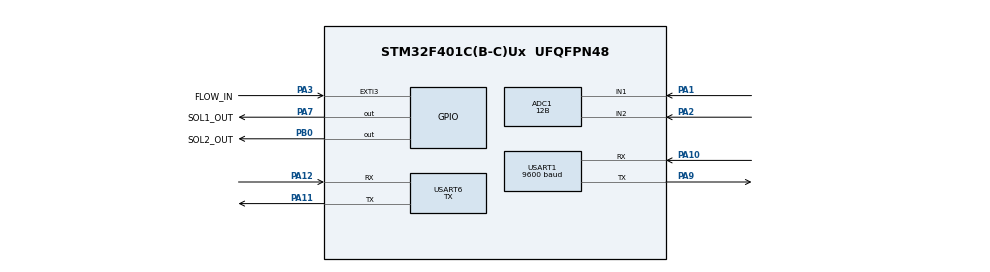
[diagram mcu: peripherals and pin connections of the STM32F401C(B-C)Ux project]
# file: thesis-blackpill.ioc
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ADC1.Channel-0\#ChannelRegularConversion=ADC_CHANNEL_1
ADC1.Channel-1\#ChannelRegularConversion=ADC_CHANNEL_2
ADC1.ClockPrescaler=ADC_CLOCK_SYNC_PCLK_DIV8
ADC1.DiscontinuousConvMode=DISABLE
ADC1.ExternalTrigConv=ADC_EXTERNALTRIGCONV_T2_TRGO
ADC1.NbrOfConversion=2
ADC1.NbrOfConversionFlag=1
ADC1.Rank-0\#ChannelRegularConversion=1
ADC1.Rank-1\#ChannelRegularConversion=2
ADC1.Resolution=ADC_RESOLUTION_12B
ADC1.SamplingTime-0\#ChannelRegularConversion=ADC_SAMPLETIME_480CYCLES
ADC1.SamplingTime-1\#ChannelRegularConversion=ADC_SAMPLETIME_480CYCLES
ADC1.ScanConvMode=ENABLE
ADC1.master=1
Dma.ADC1.3.Direction=DMA_PERIPH_TO_MEMORY
Dma.ADC1.3.FIFOMode=DMA_FIFOMODE_DISABLE
Dma.ADC1.3.Instance=DMA2_Stream0
Dma.ADC1.3.MemDataAlignment=DMA_MDATAALIGN_HALFWORD
Dma.ADC1.3.MemInc=DMA_MINC_ENABLE
Dma.ADC1.3.Mode=DMA_CIRCULAR
Dma.ADC1.3.PeriphDataAlignment=DMA_PDATAALIGN_HALFWORD
Dma.ADC1.3.PeriphInc=DMA_PINC_DISABLE
Dma.ADC1.3.Priority=DMA_PRIORITY_LOW
Dma.Request0=USART1_RX
Dma.Request1=USART1_TX
Dma.Request2=USART6_TX
Dma.Request3=ADC1
Dma.USART1_RX.0.Direction=DMA_PERIPH_TO_MEMORY
Dma.USART1_RX.0.FIFOMode=DMA_FIFOMODE_DISABLE
Dma.USART1_RX.0.Instance=DMA2_Stream2
Dma.USART1_RX.0.MemDataAlignment=DMA_MDATAALIGN_BYTE
Dma.USART1_RX.0.MemInc=DMA_MINC_ENABLE
Dma.USART1_RX.0.Mode=DMA_CIRCULAR
Dma.USART1_RX.0.PeriphDataAlignment=DMA_PDATAALIGN_BYTE
Dma.USART1_RX.0.PeriphInc=DMA_PINC_DISABLE
Dma.USART1_RX.0.Priority=DMA_PRIORITY_LOW
Dma.USART1_TX.1.Direction=DMA_MEMORY_TO_PERIPH
Dma.USART1_TX.1.FIFOMode=DMA_FIFOMODE_DISABLE
Dma.USART1_TX.1.Instance=DMA2_Stream7
Dma.USART1_TX.1.MemDataAlignment=DMA_MDATAALIGN_BYTE
Dma.USART1_TX.1.MemInc=DMA_MINC_ENABLE
Dma.USART1_TX.1.Mode=DMA_NORMAL
Dma.USART1_TX.1.PeriphDataAlignment=DMA_PDATAALIGN_BYTE
Dma.USART1_TX.1.PeriphInc=DMA_PINC_DISABLE
Dma.USART1_TX.1.Priority=DMA_PRIORITY_LOW
Dma.USART6_TX.2.Direction=DMA_MEMORY_TO_PERIPH
Dma.USART6_TX.2.FIFOMode=DMA_FIFOMODE_DISABLE
Dma.USART6_TX.2.Instance=DMA2_Stream6
Dma.USART6_TX.2.MemDataAlignment=DMA_MDATAALIGN_BYTE
Dma.USART6_TX.2.MemInc=DMA_MINC_ENABLE
Dma.USART6_TX.2.Mode=DMA_NORMAL
Dma.USART6_TX.2.PeriphDataAlignment=DMA_PDATAALIGN_BYTE
Dma.USART6_TX.2.PeriphInc=DMA_PINC_DISABLE
Dma.USART6_TX.2.Priority=DMA_PRIORITY_LOW
Mcu.Family=STM32F4
Mcu.Name=STM32F401C(B-C)Ux
Mcu.Package=UFQFPN48
NVIC.ADC_IRQn=true\:0\:0\:false\:false\:true\:true\:true\:true
NVIC.DMA2_Stream0_IRQn=true\:0\:0\:false\:false\:true\:false\:true\:true
NVIC.DMA2_Stream2_IRQn=true\:0\:0\:false\:false\:true\:false\:true\:true
NVIC.DMA2_Stream6_IRQn=true\:0\:0\:false\:false\:true\:false\:true\:true
NVIC.DMA2_Stream7_IRQn=true\:0\:0\:false\:false\:true\:false\:true\:true
NVIC.EXTI3_IRQn=true\:0\:0\:false\:false\:true\:true\:true\:true
NVIC.PriorityGroup=NVIC_PRIORITYGROUP_4
NVIC.TIM1_TRG_COM_TIM11_IRQn=true\:0\:0\:false\:false\:true\:true\:true\:true
NVIC.TIM1_UP_TIM10_IRQn=true\:0\:0\:false\:false\:true\:true\:true\:true
NVIC.USART1_IRQn=true\:0\:0\:false\:false\:true\:true\:true\:true
PA1.Signal=ADCx_IN1
PA10.Mode=Asynchronous
PA10.Signal=USART1_RX
PA11.Mode=Asynchronous
PA11.Signal=USART6_TX
PA12.Mode=Asynchronous
PA12.Signal=USART6_RX
PA13.Mode=Serial_Wire
PA13.Signal=SYS_JTMS-SWDIO
PA14.Mode=Serial_Wire
PA14.Signal=SYS_JTCK-SWCLK
PA2.Signal=ADCx_IN2
PA3.GPIO_Label=FLOW_IN
PA3.Signal=GPXTI3
PA7.GPIO_Label=SOL1_OUT
PA7.GPIO_Speed=GPIO_SPEED_FREQ_VERY_HIGH
PA7.PinState=GPIO_PIN_SET
PA7.Signal=GPIO_Output
PA9.Mode=Asynchronous
PA9.Signal=USART1_TX
PB0.GPIO_Label=SOL2_OUT
PB0.GPIO_Speed=GPIO_SPEED_FREQ_VERY_HIGH
PB0.PinState=GPIO_PIN_SET
PB0.Signal=GPIO_Output
PC14-OSC32_IN.Mode=LSE-External-Clock-Source
PC14-OSC32_IN.Signal=RCC_OSC32_IN
PC15-OSC32_OUT.Mode=LSE-External-Clock-Source
PC15-OSC32_OUT.Signal=RCC_OSC32_OUT
ProjectManager.HeapSize=0x200
ProjectManager.StackSize=0x400
ProjectManager.TargetToolchain=STM32CubeIDE
RCC.AHBFreq_Value=16000000
RCC.APB1Freq_Value=16000000
RCC.APB2Freq_Value=16000000
RCC.CortexFreq_Value=16000000
RCC.HSE_VALUE=25000000
RCC.HSI_VALUE=16000000
RCC.LSE_VALUE=32768
RCC.SYSCLKFreq_VALUE=16000000
RCC.VCOOutputFreq_Value=192000000
SH.ADCx_IN1.0=ADC1_IN1,IN1
SH.ADCx_IN2.0=ADC1_IN2,IN2
TIM10.Channel=TIM_CHANNEL_1
TIM10.Period=999
TIM10.Prescaler=15999
TIM11.Channel=TIM_CHANNEL_1
TIM11.Period=999
TIM11.Prescaler=15999
TIM2.Channel-Output\ Compare1\ No\ Output=TIM_CHANNEL_1
TIM2.Period=249
TIM2.Prescaler=15999
TIM2.TIM_MasterOutputTrigger=TIM_TRGO_UPDATE
USART1.BaudRate=9600
USART1.VirtualMode=VM_ASYNC
USART6.Mode=MODE_TX
USART6.VirtualMode=VM_ASYNC
VP_TIM10_VS_ClockSourceINT.Mode=Enable_Timer
VP_TIM10_VS_no_output1.Mode=Output Compare1 No Output
VP_TIM11_VS_ClockSourceINT.Mode=Enable_Timer
VP_TIM11_VS_no_output1.Mode=Output Compare1 No Output
VP_TIM2_VS_ClockSourceINT.Mode=Internal
VP_TIM2_VS_no_output1.Mode=Output Compare1 No Output
board=custom

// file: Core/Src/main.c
/* USER CODE BEGIN Header */
/**
  ******************************************************************************
  * @file           : main.c
  * @brief          : Main program body
  ******************************************************************************
  * @attention
  *
  * Copyright (c) 2025 STMicroelectronics.
  * All rights reserved.
  *
  * This software is licensed under terms that can be found in the LICENSE file
  * in the root directory of this software component.
  * If no LICENSE file comes with this software, it is provided AS-IS.
  *
  ******************************************************************************
  */
/* USER CODE END Header */
#include "main.h"
#include "adc.h"
#include "dma.h"
#include "tim.h"
#include "usart.h"
#include "gpio.h"

/* USER CODE BEGIN Includes */
#include "uph_fsm.h"
/* USER CODE END Includes */

void SystemClock_Config(void);

int main(void)
{

  /* MCU Configuration--------------------------------------------------------*/

  /* Reset of all peripherals, Initializes the Flash interface and the Systick. */
  LL_APB2_GRP1_EnableClock(LL_APB2_GRP1_PERIPH_SYSCFG);
  LL_APB1_GRP1_EnableClock(LL_APB1_GRP1_PERIPH_PWR);

  /* System interrupt init*/
  NVIC_SetPriorityGrouping(NVIC_PRIORITYGROUP_4);

  /* SysTick_IRQn interrupt configuration */
  NVIC_SetPriority(SysTick_IRQn, NVIC_EncodePriority(NVIC_GetPriorityGrouping(),15, 0));

  /* Configure the system clock */
  SystemClock_Config();

  /* Initialize all configured peripherals */
  MX_GPIO_Init();
  MX_DMA_Init();
  MX_ADC1_Init();
  MX_TIM10_Init();
  MX_TIM11_Init();
  MX_USART1_UART_Init();
  MX_USART6_UART_Init();
  MX_TIM2_Init();
  /* USER CODE BEGIN 2 */
  fsm_init();
  /* USER CODE END 2 */

  /* Infinite loop */
  /* USER CODE BEGIN WHILE */
  while (1)
  {
	  fsm_run();
    /* USER CODE END WHILE */

  }
}

void SystemClock_Config(void)
{
  LL_FLASH_SetLatency(LL_FLASH_LATENCY_0);
  while(LL_FLASH_GetLatency()!= LL_FLASH_LATENCY_0)
  {
  }
  LL_PWR_SetRegulVoltageScaling(LL_PWR_REGU_VOLTAGE_SCALE2);
  LL_RCC_HSI_SetCalibTrimming(16);
  LL_RCC_HSI_Enable();

   /* Wait till HSI is ready */
  while(LL_RCC_HSI_IsReady() != 1)
  {

  }
  LL_RCC_SetAHBPrescaler(LL_RCC_SYSCLK_DIV_1);
  LL_RCC_SetAPB1Prescaler(LL_RCC_APB1_DIV_1);
  LL_RCC_SetAPB2Prescaler(LL_RCC_APB2_DIV_1);
  LL_RCC_SetSysClkSource(LL_RCC_SYS_CLKSOURCE_HSI);

   /* Wait till System clock is ready */
  while(LL_RCC_GetSysClkSource() != LL_RCC_SYS_CLKSOURCE_STATUS_HSI)
  {

  }
  LL_Init1msTick(16000000);
  LL_SetSystemCoreClock(16000000);
  LL_RCC_SetTIMPrescaler(LL_RCC_TIM_PRESCALER_TWICE);
}

void Error_Handler(void)
{
  __disable_irq();
  while (1)
  {
  }
}
